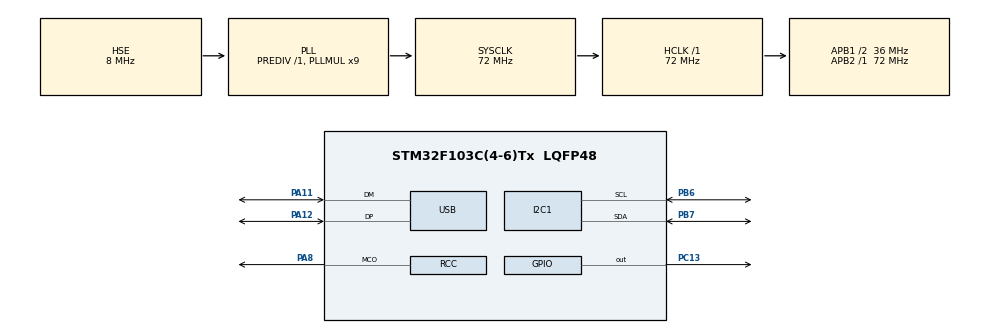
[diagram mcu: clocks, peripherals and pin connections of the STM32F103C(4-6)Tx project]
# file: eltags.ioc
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Dma.I2C1_TX.0.Direction=DMA_MEMORY_TO_PERIPH
Dma.I2C1_TX.0.Instance=DMA1_Channel6
Dma.I2C1_TX.0.MemDataAlignment=DMA_MDATAALIGN_BYTE
Dma.I2C1_TX.0.MemInc=DMA_MINC_ENABLE
Dma.I2C1_TX.0.Mode=DMA_NORMAL
Dma.I2C1_TX.0.PeriphDataAlignment=DMA_PDATAALIGN_BYTE
Dma.I2C1_TX.0.PeriphInc=DMA_PINC_DISABLE
Dma.I2C1_TX.0.Priority=DMA_PRIORITY_MEDIUM
Dma.Request0=I2C1_TX
Mcu.Family=STM32F1
Mcu.Name=STM32F103C(4-6)Tx
Mcu.Package=LQFP48
NVIC.DMA1_Channel6_IRQn=true\:0\:0\:false\:false\:true\:false\:true\:true
NVIC.PriorityGroup=NVIC_PRIORITYGROUP_4
NVIC.USB_LP_CAN1_RX0_IRQn=true\:0\:0\:false\:false\:true\:false\:true\:true
PA11.Mode=Device
PA11.Signal=USB_DM
PA12.Mode=Device
PA12.Signal=USB_DP
PA13.Mode=Serial_Wire
PA13.Signal=SYS_JTMS-SWDIO
PA14.Mode=Serial_Wire
PA14.Signal=SYS_JTCK-SWCLK
PA8.Mode=Clock-out
PA8.Signal=RCC_MCO
PB6.Mode=I2C
PB6.Signal=I2C1_SCL
PB7.Mode=I2C
PB7.Signal=I2C1_SDA
PC13-TAMPER-RTC.Signal=GPIO_Output
PC14-OSC32_IN.Mode=LSE-External-Oscillator
PC14-OSC32_IN.Signal=RCC_OSC32_IN
PC15-OSC32_OUT.Mode=LSE-External-Oscillator
PC15-OSC32_OUT.Signal=RCC_OSC32_OUT
PD0-OSC_IN.Mode=HSE-External-Oscillator
PD0-OSC_IN.Signal=RCC_OSC_IN
PD1-OSC_OUT.Mode=HSE-External-Oscillator
PD1-OSC_OUT.Signal=RCC_OSC_OUT
ProjectManager.HeapSize=0x200
ProjectManager.StackSize=0x400
ProjectManager.TargetToolchain=Makefile
RCC.AHBFreq_Value=72000000
RCC.APB1CLKDivider=RCC_HCLK_DIV2
RCC.APB1Freq_Value=36000000
RCC.APB1TimFreq_Value=72000000
RCC.APB2Freq_Value=72000000
RCC.APB2TimFreq_Value=72000000
RCC.HCLKFreq_Value=72000000
RCC.PLLMUL=RCC_PLL_MUL9
RCC.RCC_MCOSource=RCC_MCO1SOURCE_PLLCLK
RCC.SYSCLKFreq_VALUE=72000000
RCC.SYSCLKSource=RCC_SYSCLKSOURCE_PLLCLK
RCC.USBFreq_Value=48000000
RCC.USBPrescaler=RCC_USBCLKSOURCE_PLL_DIV1_5
USB_DEVICE.CLASS_NAME_FS=CDC
USB_DEVICE.VirtualMode=Cdc
USB_DEVICE.VirtualModeFS=Cdc_FS
VP_USB_DEVICE_VS_USB_DEVICE_CDC_FS.Mode=CDC_FS
board=custom

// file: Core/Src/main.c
/* USER CODE BEGIN Header */
/**
  ******************************************************************************
  * @file           : main.c
  * @brief          : Main program body
  ******************************************************************************
  * @attention
  *
  * Copyright (c) 2022 STMicroelectronics.
  * All rights reserved.
  *
  * This software is licensed under terms that can be found in the LICENSE file
  * in the root directory of this software component.
  * If no LICENSE file comes with this software, it is provided AS-IS.
  *
  ******************************************************************************
  */
/* USER CODE END Header */
#include "main.h"
#include "dma.h"
#include "i2c.h"
#include "usb_device.h"
#include "gpio.h"
#include "lcd.h"
#include "usbd_cdc_if.h"

extern USBD_HandleTypeDef hUsbDeviceFS;

void SystemClock_Config(void);
void handle_protocol_data(unsigned char c);

unsigned char usb_buf[RX_DATA_SIZE];
unsigned char *pusb_rec = usb_buf;
unsigned char *pusb_handle = usb_buf;

void app_handle_usb_data(unsigned char s)
{
	if (s == 0) {
		lcd_flush();
	} else {
		lcd_put_char(s);
	}
}

int main(void)
{

  /* MCU Configuration--------------------------------------------------------*/

  /* Reset of all peripherals, Initializes the Flash interface and the Systick. */
  HAL_Init();

  /* Configure the system clock */
  SystemClock_Config();

  /* Initialize all configured peripherals */
  MX_GPIO_Init();
  MX_DMA_Init();
  MX_I2C1_Init();
  MX_USB_DEVICE_Init();
  /* USER CODE BEGIN 2 */
  OLED_init();
  lcd_flush();
  lcd_put_string("CYG PLATFORM\n\nLINUX DEBUG TOOLS\n\nBY: FUYAO");

  /* USER CODE END 2 */

  /* Infinite loop */
  while (1)
  {

	  while (pusb_rec != pusb_handle) {
		  unsigned char *next_pusb_handle;
		  unsigned char byte;

		  if (pusb_handle == usb_buf_end)
			  next_pusb_handle = usb_buf_start;

		  else
			  next_pusb_handle = pusb_handle + 1;

		  byte = *pusb_handle;
		  pusb_handle = next_pusb_handle;

		  /* handle_protocol_data(byte); */
		  handle_protocol_data(byte);

		  if (pusb_rec == pusb_handle)
			  USBD_CDC_ReceivePacket(&hUsbDeviceFS);
	  }

	  /* HAL_GPIO_TogglePin(GPIOC, GPIO_PIN_13); */
	  /*
	   * Picture_ReverseDisplay();
	   * HAL_Delay(1000);
	   */

  }
}

void SystemClock_Config(void)
{
  RCC_OscInitTypeDef RCC_OscInitStruct = {0};
  RCC_ClkInitTypeDef RCC_ClkInitStruct = {0};
  RCC_PeriphCLKInitTypeDef PeriphClkInit = {0};

  /** Initializes the RCC Oscillators according to the specified parameters
  * in the RCC_OscInitTypeDef structure.
  */
  RCC_OscInitStruct.OscillatorType = RCC_OSCILLATORTYPE_HSE;
  RCC_OscInitStruct.HSEState = RCC_HSE_ON;
  RCC_OscInitStruct.HSEPredivValue = RCC_HSE_PREDIV_DIV1;
  RCC_OscInitStruct.HSIState = RCC_HSI_ON;
  RCC_OscInitStruct.PLL.PLLState = RCC_PLL_ON;
  RCC_OscInitStruct.PLL.PLLSource = RCC_PLLSOURCE_HSE;
  RCC_OscInitStruct.PLL.PLLMUL = RCC_PLL_MUL9;
  if (HAL_RCC_OscConfig(&RCC_OscInitStruct) != HAL_OK)
  {
    Error_Handler();
  }

  /** Initializes the CPU, AHB and APB buses clocks
  */
  RCC_ClkInitStruct.ClockType = RCC_CLOCKTYPE_HCLK|RCC_CLOCKTYPE_SYSCLK
                              |RCC_CLOCKTYPE_PCLK1|RCC_CLOCKTYPE_PCLK2;
  RCC_ClkInitStruct.SYSCLKSource = RCC_SYSCLKSOURCE_PLLCLK;
  RCC_ClkInitStruct.AHBCLKDivider = RCC_SYSCLK_DIV1;
  RCC_ClkInitStruct.APB1CLKDivider = RCC_HCLK_DIV2;
  RCC_ClkInitStruct.APB2CLKDivider = RCC_HCLK_DIV1;

  if (HAL_RCC_ClockConfig(&RCC_ClkInitStruct, FLASH_LATENCY_2) != HAL_OK)
  {
    Error_Handler();
  }
  PeriphClkInit.PeriphClockSelection = RCC_PERIPHCLK_USB;
  PeriphClkInit.UsbClockSelection = RCC_USBCLKSOURCE_PLL_DIV1_5;
  if (HAL_RCCEx_PeriphCLKConfig(&PeriphClkInit) != HAL_OK)
  {
    Error_Handler();
  }
  HAL_RCC_MCOConfig(RCC_MCO, RCC_MCO1SOURCE_HSE, RCC_MCODIV_1);
}

void Error_Handler(void)
{
  __disable_irq();
  while (1)
  {
  }
}
